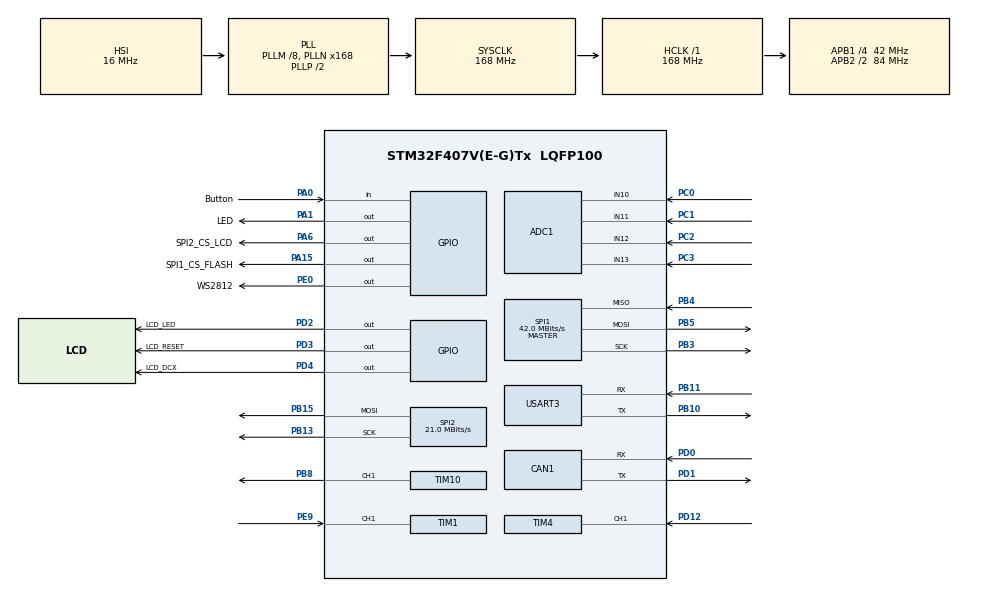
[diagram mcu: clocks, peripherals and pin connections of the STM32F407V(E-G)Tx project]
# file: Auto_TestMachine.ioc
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ADC1.Channel-0\#ChannelRegularConversion=ADC_CHANNEL_10
ADC1.Channel-1\#ChannelRegularConversion=ADC_CHANNEL_11
ADC1.Channel-2\#ChannelRegularConversion=ADC_CHANNEL_12
ADC1.Channel-3\#ChannelRegularConversion=ADC_CHANNEL_13
ADC1.ContinuousConvMode=ENABLE
ADC1.DMAContinuousRequests=ENABLE
ADC1.NbrOfConversion=4
ADC1.NbrOfConversionFlag=1
ADC1.Rank-0\#ChannelRegularConversion=1
ADC1.Rank-1\#ChannelRegularConversion=2
ADC1.Rank-2\#ChannelRegularConversion=3
ADC1.Rank-3\#ChannelRegularConversion=4
ADC1.SamplingTime-0\#ChannelRegularConversion=ADC_SAMPLETIME_28CYCLES
ADC1.SamplingTime-1\#ChannelRegularConversion=ADC_SAMPLETIME_28CYCLES
ADC1.SamplingTime-2\#ChannelRegularConversion=ADC_SAMPLETIME_28CYCLES
ADC1.SamplingTime-3\#ChannelRegularConversion=ADC_SAMPLETIME_28CYCLES
ADC1.master=1
CAN1.ABOM=ENABLE
CAN1.AWUM=ENABLE
CAN1.BS1=CAN_BS1_16TQ
CAN1.BS2=CAN_BS2_8TQ
CAN1.CalculateTimeQuantum=380.95238095238096
Dma.ADC1.0.Direction=DMA_PERIPH_TO_MEMORY
Dma.ADC1.0.FIFOMode=DMA_FIFOMODE_DISABLE
Dma.ADC1.0.Instance=DMA2_Stream0
Dma.ADC1.0.MemDataAlignment=DMA_MDATAALIGN_HALFWORD
Dma.ADC1.0.MemInc=DMA_MINC_ENABLE
Dma.ADC1.0.Mode=DMA_CIRCULAR
Dma.ADC1.0.PeriphDataAlignment=DMA_PDATAALIGN_HALFWORD
Dma.ADC1.0.PeriphInc=DMA_PINC_DISABLE
Dma.ADC1.0.Priority=DMA_PRIORITY_LOW
Dma.Request0=ADC1
Dma.Request1=USART3_RX
Dma.USART3_RX.1.Direction=DMA_PERIPH_TO_MEMORY
Dma.USART3_RX.1.FIFOMode=DMA_FIFOMODE_DISABLE
Dma.USART3_RX.1.Instance=DMA1_Stream1
Dma.USART3_RX.1.MemDataAlignment=DMA_MDATAALIGN_BYTE
Dma.USART3_RX.1.MemInc=DMA_MINC_ENABLE
Dma.USART3_RX.1.Mode=DMA_CIRCULAR
Dma.USART3_RX.1.PeriphDataAlignment=DMA_PDATAALIGN_BYTE
Dma.USART3_RX.1.PeriphInc=DMA_PINC_DISABLE
Dma.USART3_RX.1.Priority=DMA_PRIORITY_LOW
FREERTOS.Tasks01=Init_Task,24,512,Init_taskFunction,As weak,NULL,Dynamic,NULL,NULL
FREERTOS.Timers01=Detect_Timer,Detect_Timer_Callback,osTimerPeriodic,As weak,NULL,Dynamic,NULL
IWDG.Prescaler=IWDG_PRESCALER_32
IWDG.Reload=1000
Mcu.Family=STM32F4
Mcu.Name=STM32F407V(E-G)Tx
Mcu.Package=LQFP100
NVIC.CAN1_RX1_IRQn=true\:5\:0\:false\:false\:true\:true\:true\:true
NVIC.DMA1_Stream1_IRQn=true\:5\:0\:false\:false\:true\:true\:false\:true
NVIC.DMA2_Stream0_IRQn=true\:5\:0\:false\:false\:true\:true\:false\:true
NVIC.PriorityGroup=NVIC_PRIORITYGROUP_4
NVIC.TIM3_IRQn=true\:0\:0\:false\:false\:true\:false\:false\:true
NVIC.TimeBase=TIM3_IRQn
NVIC.TimeBaseIP=TIM3
NVIC.USART3_IRQn=true\:5\:0\:true\:false\:true\:true\:true\:false
PA0-WKUP.GPIO_Label=Button
PA0-WKUP.GPIO_PuPd=GPIO_PULLDOWN
PA0-WKUP.Signal=GPIO_Input
PA1.GPIO_Label=LED
PA1.Signal=GPIO_Output
PA13.Mode=Serial_Wire
PA13.Signal=SYS_JTMS-SWDIO
PA14.Mode=Serial_Wire
PA14.Signal=SYS_JTCK-SWCLK
PA15.GPIO_Label=SPI1_CS_FLASH
PA15.Signal=GPIO_Output
PA6.GPIO_Label=SPI2_CS_LCD
PA6.Signal=GPIO_Output
PB10.Mode=Asynchronous
PB10.Signal=USART3_TX
PB11.Mode=Asynchronous
PB11.Signal=USART3_RX
PB13.Mode=TX_Only_Simplex_Unidirect_Master
PB13.Signal=SPI2_SCK
PB15.Mode=TX_Only_Simplex_Unidirect_Master
PB15.Signal=SPI2_MOSI
PB3.Mode=Full_Duplex_Master
PB3.Signal=SPI1_SCK
PB4.Mode=Full_Duplex_Master
PB4.Signal=SPI1_MISO
PB5.Mode=Full_Duplex_Master
PB5.Signal=SPI1_MOSI
PB8.Signal=S_TIM10_CH1
PC0.Signal=ADCx_IN10
PC1.Signal=ADCx_IN11
PC14-OSC32_IN.Mode=LSE-External-Oscillator
PC14-OSC32_IN.Signal=RCC_OSC32_IN
PC15-OSC32_OUT.Mode=LSE-External-Oscillator
PC15-OSC32_OUT.Signal=RCC_OSC32_OUT
PC2.Signal=ADCx_IN12
PC3.Signal=ADCx_IN13
PD0.Mode=Master
PD0.Signal=CAN1_RX
PD1.Mode=Master
PD1.Signal=CAN1_TX
PD12.Signal=S_TIM4_CH1
PD2.GPIO_Label=LCD_LED
PD2.Signal=GPIO_Output
PD3.GPIO_Label=LCD_RESET
PD3.Signal=GPIO_Output
PD4.GPIO_Label=LCD_DCX
PD4.Signal=GPIO_Output
PE0.GPIO_Label=WS2812
PE0.GPIO_Speed=GPIO_SPEED_FREQ_MEDIUM
PE0.Signal=GPIO_Output
PE9.Signal=S_TIM1_CH1
PH0-OSC_IN.Mode=HSE-External-Oscillator
PH0-OSC_IN.Signal=RCC_OSC_IN
PH1-OSC_OUT.Mode=HSE-External-Oscillator
PH1-OSC_OUT.Signal=RCC_OSC_OUT
ProjectManager.HeapSize=0x200
ProjectManager.StackSize=0x400
ProjectManager.TargetToolchain=MDK-ARM V5.27
RCC.48MHZClocksFreq_Value=84000000
RCC.AHBFreq_Value=168000000
RCC.APB1CLKDivider=RCC_HCLK_DIV4
RCC.APB1Freq_Value=42000000
RCC.APB1TimFreq_Value=84000000
RCC.APB2CLKDivider=RCC_HCLK_DIV2
RCC.APB2Freq_Value=84000000
RCC.APB2TimFreq_Value=168000000
RCC.CortexFreq_Value=168000000
RCC.HCLKFreq_Value=168000000
RCC.HSE_VALUE=25000000
RCC.HSI_VALUE=16000000
RCC.PLLM=8
RCC.PLLN=168
RCC.SYSCLKFreq_VALUE=168000000
RCC.SYSCLKSource=RCC_SYSCLKSOURCE_PLLCLK
RCC.VCOOutputFreq_Value=336000000
SH.ADCx_IN10.0=ADC1_IN10,IN10
SH.ADCx_IN11.0=ADC1_IN11,IN11
SH.ADCx_IN12.0=ADC1_IN12,IN12
SH.ADCx_IN13.0=ADC1_IN13,IN13
SH.S_TIM10_CH1.0=TIM10_CH1,PWM Generation1 CH1
SH.S_TIM1_CH1.0=TIM1_CH1,TriggerSource_TI1FP1
SH.S_TIM1_CH1.1=TIM1_CH1,Input_Capture1_from_TI1
SH.S_TIM1_CH1.2=TIM1_CH1,Input_Capture2_from_TI1
SH.S_TIM4_CH1.0=TIM4_CH1,Input_Capture1_from_TI1
SH.S_TIM4_CH1.1=TIM4_CH1,Input_Capture2_from_TI1
SH.S_TIM4_CH1.2=TIM4_CH1,TriggerSource_TI1FP1
SPI1.CalculateBaudRate=42.0 MBits/s
SPI1.Direction=SPI_DIRECTION_2LINES
SPI1.Mode=SPI_MODE_MASTER
SPI1.VirtualType=VM_MASTER
SPI2.CalculateBaudRate=21.0 MBits/s
SPI2.Direction=SPI_DIRECTION_2LINES
SPI2.Mode=SPI_MODE_MASTER
SPI2.VirtualType=VM_MASTER
TIM1.AutoReloadPreload=TIM_AUTORELOAD_PRELOAD_ENABLE
TIM1.Channel-Input_Capture1_from_TI1=TIM_CHANNEL_1
TIM1.Channel-Input_Capture2_from_TI1=TIM_CHANNEL_2
TIM1.ICPolarity_CH2=TIM_INPUTCHANNELPOLARITY_FALLING
TIM1.Period=65535
TIM1.Prescaler=167
TIM10.Channel=TIM_CHANNEL_1
TIM10.Period=2499
TIM10.Prescaler=83
TIM10.Pulse=1000
TIM4.AutoReloadPreload=TIM_AUTORELOAD_PRELOAD_ENABLE
TIM4.Channel-Input_Capture1_from_TI1=TIM_CHANNEL_1
TIM4.Channel-Input_Capture2_from_TI1=TIM_CHANNEL_2
TIM4.ICPolarity_CH2=TIM_INPUTCHANNELPOLARITY_FALLING
TIM4.Period=65535
TIM4.Prescaler=83
USART3.VirtualMode=VM_ASYNC
VP_FREERTOS_VS_CMSIS_V2.Mode=CMSIS_V2
VP_IWDG_VS_IWDG.Mode=IWDG_Activate
VP_SYS_VS_tim3.Mode=TIM3
VP_TIM10_VS_ClockSourceINT.Mode=Enable_Timer
VP_TIM1_VS_ClockSourceINT.Mode=Internal
VP_TIM1_VS_ControllerModeReset.Mode=Reset Mode
VP_TIM4_VS_ClockSourceINT.Mode=Internal
VP_TIM4_VS_ControllerModeReset.Mode=Reset Mode
board=custom

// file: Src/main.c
/* USER CODE BEGIN Header */
/**
 ******************************************************************************
 * @file           : main.c
 * @brief          : Main program body
 ******************************************************************************
 * @attention
 *
 * <h2><center>&copy; Copyright (c) 2022 STMicroelectronics.
 * All rights reserved.</center></h2>
 *
 * This software component is licensed by ST under Ultimate Liberty license
 * SLA0044, the "License"; You may not use this file except in compliance with
 * the License. You may obtain a copy of the License at:
 *                             www.st.com/SLA0044
 *
 ******************************************************************************
 */
/* USER CODE END Header */

#include "main.h"
#include "cmsis_os.h"
#include "adc.h"
#include "can.h"
#include "dma.h"
#include "iwdg.h"
#include "spi.h"
#include "tim.h"
#include "usart.h"
#include "gpio.h"

/* USER CODE BEGIN Includes */
#include "watchdog.h"
/* USER CODE END Includes */

void SystemClock_Config(void);
void MX_FREERTOS_Init(void);

int main(void)
{

  /* MCU Configuration--------------------------------------------------------*/

  /* Reset of all peripherals, Initializes the Flash interface and the Systick. */
  HAL_Init();

  /* Configure the system clock */
  SystemClock_Config();

  /* Initialize all configured peripherals */
  MX_GPIO_Init();
  MX_DMA_Init();
  MX_ADC1_Init();
  MX_USART3_UART_Init();
  MX_CAN1_Init();
  MX_IWDG_Init();
  MX_SPI1_Init();
  MX_SPI2_Init();
  MX_TIM1_Init();
  MX_TIM4_Init();
  MX_TIM10_Init();
  /* USER CODE BEGIN 2 */
	FeedIndependentWDOG();
	HAL_TIM_Base_Start_IT(&htim10);
  /* USER CODE END 2 */

  /* Init scheduler */
  osKernelInitialize();  /* Call init function for freertos objects (in freertos.c) */
  MX_FREERTOS_Init();
  /* Start scheduler */
  osKernelStart();

  /* We should never get here as control is now taken by the scheduler */
  /* Infinite loop */
	while(1) {

	}
}

void SystemClock_Config(void)
{
  RCC_OscInitTypeDef RCC_OscInitStruct = {0};
  RCC_ClkInitTypeDef RCC_ClkInitStruct = {0};

  /** Configure the main internal regulator output voltage
  */
  __HAL_RCC_PWR_CLK_ENABLE();
  __HAL_PWR_VOLTAGESCALING_CONFIG(PWR_REGULATOR_VOLTAGE_SCALE1);
  /** Initializes the CPU, AHB and APB busses clocks
  */
  RCC_OscInitStruct.OscillatorType = RCC_OSCILLATORTYPE_HSI|RCC_OSCILLATORTYPE_LSI;
  RCC_OscInitStruct.HSIState = RCC_HSI_ON;
  RCC_OscInitStruct.HSICalibrationValue = RCC_HSICALIBRATION_DEFAULT;
  RCC_OscInitStruct.LSIState = RCC_LSI_ON;
  RCC_OscInitStruct.PLL.PLLState = RCC_PLL_ON;
  RCC_OscInitStruct.PLL.PLLSource = RCC_PLLSOURCE_HSI;
  RCC_OscInitStruct.PLL.PLLM = 8;
  RCC_OscInitStruct.PLL.PLLN = 168;
  RCC_OscInitStruct.PLL.PLLP = RCC_PLLP_DIV2;
  RCC_OscInitStruct.PLL.PLLQ = 4;
  if (HAL_RCC_OscConfig(&RCC_OscInitStruct) != HAL_OK)
  {
    Error_Handler();
  }
  /** Initializes the CPU, AHB and APB busses clocks
  */
  RCC_ClkInitStruct.ClockType = RCC_CLOCKTYPE_HCLK|RCC_CLOCKTYPE_SYSCLK
                              |RCC_CLOCKTYPE_PCLK1|RCC_CLOCKTYPE_PCLK2;
  RCC_ClkInitStruct.SYSCLKSource = RCC_SYSCLKSOURCE_PLLCLK;
  RCC_ClkInitStruct.AHBCLKDivider = RCC_SYSCLK_DIV1;
  RCC_ClkInitStruct.APB1CLKDivider = RCC_HCLK_DIV4;
  RCC_ClkInitStruct.APB2CLKDivider = RCC_HCLK_DIV2;

  if (HAL_RCC_ClockConfig(&RCC_ClkInitStruct, FLASH_LATENCY_5) != HAL_OK)
  {
    Error_Handler();
  }
}

 /**
  * @brief  Period elapsed callback in non blocking mode
  * @note   This function is called  when TIM3 interrupt took place, inside
  * HAL_TIM_IRQHandler(). It makes a direct call to HAL_IncTick() to increment
  * a global variable "uwTick" used as application time base.
  * @param  htim : TIM handle
  * @retval None
  */
void HAL_TIM_PeriodElapsedCallback(TIM_HandleTypeDef *htim)
{
  if (htim->Instance == TIM3) {
    HAL_IncTick();
  }
}

void Error_Handler(void)
{
}

/************************ (C) COPYRIGHT STMicroelectronics *****END OF FILE****/

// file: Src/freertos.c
/* USER CODE BEGIN Header */
/**
 ******************************************************************************
 * File Name          : freertos.c
 * Description        : Code for freertos applications
 ******************************************************************************
 * @attention
 *
 * <h2><center>&copy; Copyright (c) 2022 STMicroelectronics.
 * All rights reserved.</center></h2>
 *
 * This software component is licensed by ST under Ultimate Liberty license
 * SLA0044, the "License"; You may not use this file except in compliance with
 * the License. You may obtain a copy of the License at:
 *                             www.st.com/SLA0044
 *
 ******************************************************************************
 */
/* USER CODE END Header */

#include "FreeRTOS.h"
#include "task.h"
#include "main.h"
#include "cmsis_os.h"

/* USER CODE BEGIN Includes */
#include "adc.h"
#include "usart.h"
#include "button.h"
/* USER CODE END Includes */

/* Definitions for Init_Task */
osThreadId_t Init_TaskHandle;
const osThreadAttr_t Init_Task_attributes = {
  .name = "Init_Task",
  .priority = (osPriority_t) osPriorityNormal,
  .stack_size = 512 * 4
};
/* Definitions for Detect_Timer */
osTimerId_t Detect_TimerHandle;
const osTimerAttr_t Detect_Timer_attributes = {
  .name = "Detect_Timer"
};

void Init_taskFunction(void *argument);
void Detect_Timer_Callback(void *argument);

void MX_FREERTOS_Init(void); /* (MISRA C 2004 rule 8.1) */

void MX_FREERTOS_Init(void) {

  /* Create the timer(s) */
  /* creation of Detect_Timer */
  Detect_TimerHandle = osTimerNew(Detect_Timer_Callback, osTimerPeriodic, NULL, &Detect_Timer_attributes);

  /* Create the thread(s) */
  /* creation of Init_Task */
  Init_TaskHandle = osThreadNew(Init_taskFunction, NULL, &Init_Task_attributes);

}

__weak void Init_taskFunction(void *argument)
{
  /* USER CODE BEGIN Init_taskFunction */
  TickType_t xLastWakeTime;
  xLastWakeTime = xTaskGetTickCount();

  /* Infinite loop */
  for (;;)
  {
    vTaskDelayUntil(&xLastWakeTime, 1000 / portTICK_RATE_MS);
  }
  //	vTaskDelete(NULL);
  /* USER CODE END Init_taskFunction */
}

/* Detect_Timer_Callback function */
__weak void Detect_Timer_Callback(void *argument)
{
}

/************************ (C) COPYRIGHT STMicroelectronics *****END OF FILE****/
